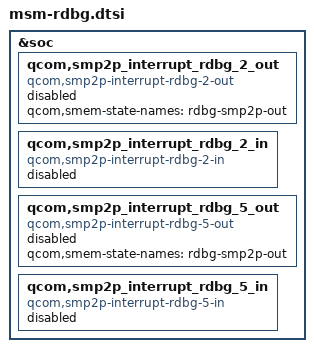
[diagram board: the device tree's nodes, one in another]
&soc {
  /* smp2p information */
	qcom,smp2p_interrupt_rdbg_2_out {
		status = "disabled";
		compatible = "qcom,smp2p-interrupt-rdbg-2-out";
		qcom,smem-state-names = "rdbg-smp2p-out";
	};

	qcom,smp2p_interrupt_rdbg_2_in {
		status = "disabled";
		compatible = "qcom,smp2p-interrupt-rdbg-2-in";
		interrupt-names = "rdbg-smp2p-in";
	};

	qcom,smp2p_interrupt_rdbg_5_out {
		status = "disabled";
		compatible = "qcom,smp2p-interrupt-rdbg-5-out";
		qcom,smem-state-names = "rdbg-smp2p-out";
	};

	qcom,smp2p_interrupt_rdbg_5_in {
		status = "disabled";
		compatible = "qcom,smp2p-interrupt-rdbg-5-in";
		interrupt-names = "rdbg-smp2p-in";
	};
};
